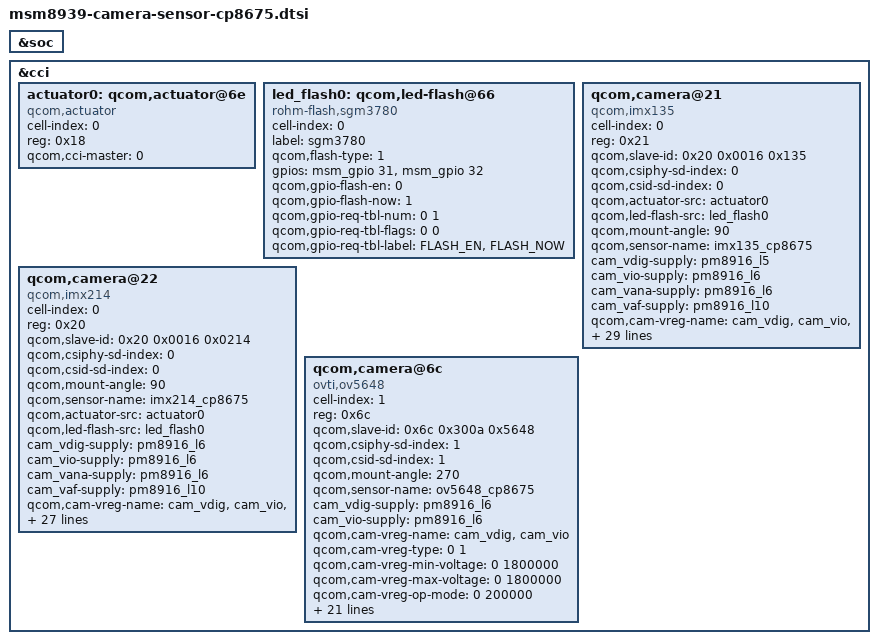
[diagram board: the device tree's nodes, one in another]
/*
 * Copyright (c) 2014, The Linux Foundation. All rights reserved.
 *
 * This program is free software; you can redistribute it and/or modify
 * it under the terms of the GNU General Public License version 2 and
 * only version 2 as published by the Free Software Foundation.
 *
 * This program is distributed in the hope that it will be useful,
 * but WITHOUT ANY WARRANTY; without even the implied warranty of
 * MERCHANTABILITY or FITNESS FOR A PARTICULAR PURPOSE.  See the
 * GNU General Public License for more details.
 */

&soc {
};

&cci {
	actuator0: qcom,actuator@6e {
		cell-index = <0>;
		reg = <0x18>;
		compatible = "qcom,actuator";
		qcom,cci-master = <0>;
	};

	led_flash0: qcom,led-flash@66 {
		cell-index = <0>;
		compatible = "rohm-flash,sgm3780";
		label = "sgm3780";
		qcom,flash-type = <1>;
		gpios = <&msm_gpio 31 0>,
			<&msm_gpio 32 0>;
		qcom,gpio-flash-en = <0>;
		qcom,gpio-flash-now = <1>;
		qcom,gpio-req-tbl-num = <0 1>;
		qcom,gpio-req-tbl-flags = <0 0>;
		qcom,gpio-req-tbl-label = "FLASH_EN",
			"FLASH_NOW";
	};

	qcom,camera@21 {
		cell-index = <0>;
		compatible = "qcom,imx135", "qcom,camera";
		reg = <0x21>;
		qcom,slave-id = <0x20 0x0016 0x135>;
		qcom,csiphy-sd-index = <0>;
		qcom,csid-sd-index = <0>;
		qcom,actuator-src = <&actuator0>;
		qcom,led-flash-src = <&led_flash0>;
		qcom,mount-angle = <90>;
		qcom,sensor-name = "imx135_cp8675";
		cam_vdig-supply = <&pm8916_l5>;
		cam_vio-supply = <&pm8916_l6>;
		cam_vana-supply = <&pm8916_l6>;
		cam_vaf-supply = <&pm8916_l10>;
		qcom,cam-vreg-name = "cam_vdig", "cam_vio", "cam_vana",
			"cam_vaf";
		qcom,cam-vreg-type = <0 1 0 0>;
		qcom,cam-vreg-min-voltage = <1800000 1800000 1800000 2800000>;
		qcom,cam-vreg-max-voltage = <1800000 1800000 1800000 2800000>;
		qcom,cam-vreg-op-mode = <200000 0 80000 100000>;
		pinctrl-names = "cam_default", "cam_suspend";
		pinctrl-0 = <&cam_sensor_mclk0_default
			&cam_sensor_rear_default>;
		pinctrl-1 = <&cam_sensor_mclk0_sleep &cam_sensor_rear_sleep>;
		qcom,gpio-no-mux = <0>;
		gpios = <&msm_gpio 26 0>,
			<&msm_gpio 16 0>,
			<&msm_gpio 119 0>,
			<&msm_gpio 120 0>,
			<&msm_gpio 34 0>;
		qcom,gpio-standby = <1>;
		qcom,gpio-vana = <2>;
		qcom,gpio-vdig = <3>;
		qcom,gpio-af-pwdm = <4>;
		qcom,gpio-req-tbl-num = <0 1 2 3 4>;
		qcom,gpio-req-tbl-flags = <1 0 0 0 0>;
		qcom,gpio-req-tbl-label = "CAMIF_MCLK",
			"CAM_STANDBY",
			"CAM_VANA",
			"CAM_VDIG",
			"CAM_AF_PWDM";
		qcom,csi-lane-assign = <0x4320>;
		qcom,csi-lane-mask = <0x1f>;
		qcom,sensor-position = <0>;
		qcom,sensor-mode = <1>;
		qcom,cci-master = <0>;
		status = "ok";
		clocks = <&clock_gcc clk_mclk0_clk_src>,
			<&clock_gcc clk_gcc_camss_mclk0_clk>;
		clock-names = "cam_src_clk", "cam_clk";
	};

	qcom,camera@22 {
		cell-index = <0>;
		compatible = "qcom,imx214", "qcom,camera";
		reg = <0x20>;
		qcom,slave-id = <0x20 0x0016 0x0214>;
		qcom,csiphy-sd-index = <0>;
		qcom,csid-sd-index = <0>;
		qcom,mount-angle = <90>;
		qcom,sensor-name = "imx214_cp8675";
		qcom,actuator-src = <&actuator0>;
		qcom,led-flash-src = <&led_flash0>;
		cam_vdig-supply = <&pm8916_l6>;
		cam_vio-supply = <&pm8916_l6>;
		cam_vana-supply = <&pm8916_l6>;
		cam_vaf-supply = <&pm8916_l10>;
		qcom,cam-vreg-name = "cam_vdig", "cam_vio", "cam_vana","cam_vaf";
		qcom,cam-vreg-type = <0 0 0 0>;
		qcom,cam-vreg-min-voltage = <0 1800000 0 2800000>;
		qcom,cam-vreg-max-voltage = <0 1800000 0 2800000>;
		qcom,cam-vreg-op-mode = <0 105000 0 100000>;
		pinctrl-names = "cam_default", "cam_suspend";
		pinctrl-0 = <&cam_sensor_mclk0_default &cam_sensor_rear_default>;
		pinctrl-1 = <&cam_sensor_mclk0_sleep &cam_sensor_rear_sleep>;
		qcom,gpio-no-mux = <0>;
		gpios = <&msm_gpio 26 0>,
			<&msm_gpio 16 0>,
			<&msm_gpio 119 0>,
			<&msm_gpio 120 0>,
			<&msm_gpio 34 0>;
		qcom,gpio-standby = <1>;
		qcom,gpio-vana = <2>;
		qcom,gpio-vdig = <3>;
		qcom,gpio-af-pwdm = <4>;
		qcom,gpio-req-tbl-num = <0 1 2 3 4>;
		qcom,gpio-req-tbl-flags = <1 0 0 0 0>;
		qcom,gpio-req-tbl-label = "CAMIF_MCLK",
			"CAM_STANDBY",
			"CAM_VANA",
			"CAM_VDIG",
			"CAM_AF_PWDM";
		qcom,csi-lane-assign = <0x4320>;
		qcom,csi-lane-mask = <0x1f>;
		qcom,sensor-position = <0>;
		qcom,sensor-mode = <1>;
		qcom,cci-master = <0>;
		status = "ok";
		clocks = <&clock_gcc clk_mclk0_clk_src>,
			<&clock_gcc clk_gcc_camss_mclk0_clk>;
		clock-names = "cam_src_clk", "cam_clk";
	};

	qcom,camera@6c {
		cell-index = <1>;
		compatible = "ovti,ov5648", "qcom,camera";
		reg = <0x6c>;
		qcom,slave-id = <0x6c 0x300a 0x5648>;
		qcom,csiphy-sd-index = <1>;
		qcom,csid-sd-index = <1>;
		qcom,mount-angle = <270>;
		qcom,sensor-name = "ov5648_cp8675";
		cam_vdig-supply = <&pm8916_l6>;
		cam_vio-supply = <&pm8916_l6>;
		qcom,cam-vreg-name = "cam_vdig", "cam_vio";
		qcom,cam-vreg-type = <0 1>;
		qcom,cam-vreg-min-voltage = <0 1800000>;
		qcom,cam-vreg-max-voltage = <0 1800000>;
		qcom,cam-vreg-op-mode = <0 200000>;
		pinctrl-names = "cam_default", "cam_suspend";
		pinctrl-0 = <&cam_sensor_mclk1_default
			&cam_sensor_front_default>;
		pinctrl-1 = <&cam_sensor_mclk1_sleep &cam_sensor_front_sleep>;
		qcom,gpio-no-mux = <0>;
		gpios = <&msm_gpio 27 0>,
			<&msm_gpio 28 0>,
			<&msm_gpio 33 0>,
			<&msm_gpio 119 0>;
		qcom,gpio-reset = <1>;
		qcom,gpio-standby = <2>;
		qcom,gpio-vana = <3>;
		qcom,gpio-req-tbl-num = <0 1 2 3>;
		qcom,gpio-req-tbl-flags = <1 0 0 0>;
		qcom,gpio-req-tbl-label = "CAMIF_MCLK",
			"CAM_RESET",
			"CAM_STANDBY",
			"CAM_VANA";
		qcom,csi-lane-assign = <0x4320>;
		qcom,csi-lane-mask = <0x07>;
		qcom,sensor-position = <1>;
		qcom,sensor-mode = <0>;
		qcom,cci-master = <0>;
		status = "ok";
		clocks = <&clock_gcc clk_mclk1_clk_src>,
			<&clock_gcc clk_gcc_camss_mclk1_clk>;
		clock-names = "cam_src_clk", "cam_clk";
	};
};
